# RN8XXX_V2 register map
File version: 1.0
Registers are 32-bit, read-write, reset 0x0 unless marked. A register's access mark holds for its fields unless they carry their own. Offsets are from the block's base; [hi:lo] are bit positions; {n}, {i} and the like mark numbered series.

## LCD — liquid crystal display
Base 0x40048000
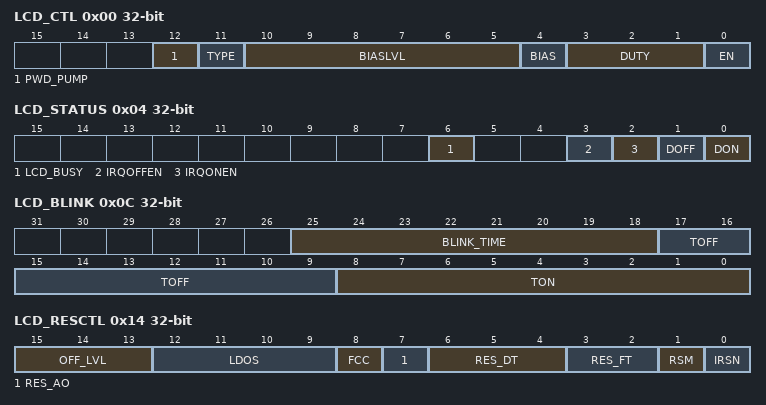
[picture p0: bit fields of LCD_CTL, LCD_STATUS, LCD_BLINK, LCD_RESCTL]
0x00 LCD_CTL — control
  [12] PWD_PUMP — PUMP disable
    0=enable (internal pump enable); 1=disable (internal pump disable.LCD drived by external voltage source)
  [11] TYPE — LCD drive type
    0=type A; 1=type B
  [10:5] BIASLVL — Bias voltage regulator
  [4] BIAS — voltage bias
    0=1/3 (1/3 voltage bias); 1=1/4 (1/4 voltage bias)
  [3:1] DUTY — duty cycle
    0=static (1 com); 1=1/2duty (2 com); 2=1/3duty (3 com); 3=1/4duty (4 com); 4=1/6duty (6 com); 5=1/8duty (8 com); 6=reserved1 (do not use); 7=reserved2 (do not use)
  [0] EN — module enable
    0=disable (module disable); 1=enable (module enable)
0x04 LCD_STATUS — status
  [6] LCD_BUSY ro — busy
    0=idle (LCD in idle state,all bit-fields in register LCD_CTL are read-write); 1=busy (LCD in working state,all bit-fields in register LCD_CTL,except EN,are read-only)
  [3] IRQOFFEN — display off interrupt enble
    0=disable (do not generate interrupt on display off event); 1=enable (generate interrupt on display off event)
  [2] IRQONEN — display on interrupt enble
    0=disable (do not generate interrupt on display on event); 1=enable (generate interrupt on display on event)
  [1] DOFF write-1-clears — display off
    0=no (no outstanding LCD display off event); 1=yes (LCD display off event pending)
  [0] DON write-1-clears — display on
    0=no (no outstanding LCD display on event); 1=yes (LCD display on event pending)
0x08 LCD_CLKDIV — clock divisor
  [7:0] CLKDIV — divisor.frequency of LCD clk is 32768/(2*(CLKDIV+1))
0x0C LCD_BLINK — blink control
  [25:18] BLINK_TIME — blink duration in 0.25s.please make sure TON equals to 2 * BLINK_TIME
  [17:9] TOFF — Off duration in 0.25s.Great than 3s in favor of better display quality.Time = 0.25 * TON .
  [8:0] TON — On duration in 0.25s.Great than 3s in favor of better display quality.Time = 0.25 * TON .
0x10 LCD_PS reset 0xCCC — PUMP set-up duration
  [11:0] PS — PUMP Set-up duration,equals 30.5us * (4 + PS)
0x14 LCD_RESCTL — registors controlling register
  [15:13] OFF_LVL — LCD off pins out signal selection
    0==LCDV0 (select LCDV0 as LCD pinout); 1==LCDVA (select LCDVA as LCD pinout); 2==LCDVB (select LCDVB as LCD pinout); 3==LCDVC (select LCDVC as LCD pinout); 4==LCDVD (select LCDVD as LCD pinout); 5==7Hz (select 7Hz as LCD pinout)
  [12:9] LDOS — LDO level selection
    0=2.7 (select 2.7V as LDO level); 1=2.76 (select 2.76V as LDO level); 2=2.82 (select 2.82V as LDO level); 3=2.88 (select 2.88V as LDO level); 4=2.94 (select 2.94V as LDO level); 5=select 3V as LDO level; 6=3.06 (select 3.06V as LDO level); 7=3.12 (select 3.12V as LDO level); 8=3.18 (select 3.18V as LDO level); 9=3.24 (select 3.24V as LDO level); 10=3.3 (select 3.3V as LDO level); 11=3.36 (select 3.36V as LDO level); 12=3.42 (select 3.42V as LDO level); 13=3.48 (select 3.48V as LDO level); 14=3.54 (select 3.54V as LDO level); 15=3.6 (select 3.6V as LDO level)
  [8] FCC — fast charging enable
    0=disable fast charging; 1=enable fast charging
  [7] RES_AO — driving mode swich
    0=switch (registors will be driven according to RES_DT and RES_FT); 1=always (registors will always be driven)
  [6:4] RES_DT — driving duration
  [3:2] RES_FT — driving frequency
    0=one (driving 1 time); 1=two (driving 2 times); 2=three (driving 3 times); 3=four (driving 4 times)
  [1] RSM — select internal registors mode
    1=big (swich between big and small registors); 0=small (swich between small and null registors)
  [0] IRSN — select registors mode
    1=extenal registors; 0=internal (enternal registors)
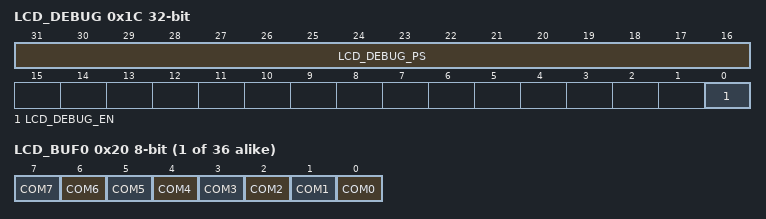
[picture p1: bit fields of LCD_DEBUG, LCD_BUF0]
0x1C LCD_DEBUG
  [31:16] LCD_DEBUG_PS — lcd debug write protect; 0xed3a:write enable
  [0] LCD_DEBUG_EN — lcd debug enable
    0=disable (lcd debug disable); 1=enable (lcd debug enable)
{0x20+i} LCD_BUF{i} 8-bit (i=0..35) — Data of SEG(x)-COM[7:0] from BUF(x)[7:0] when duty is 5,Data of SEG(x)-COM[5:0] from BUF(x)[5:0] when duty is 4,Data of SEG(2*x+1)-COM[3:0] from BUF(2*x)[7:4] and SEG(2*x)-COM[3:0] from BUF(2*x)[3:0] when duty is 3
  [all] fields
    0=off (segment turn off); 1=on (segment turn on)
  [n] COM{n} (n=4..7) — COM{n} or COM{n-4}(when duty less or equal than 3)
  [n] COM{n} (n=0..3)
